# RP2350 register map
Vendor: Raspberry Pi; Series: RP; File version: 0.1
CPU: CM33 r1p0, little endian, MPU, FPU, DSP, VTOR, 4 interrupt priority bits, 52 interrupts, 8 SAU regions
Registers are 32-bit, read-write, reset 0x0 unless marked. A register's access mark holds for its fields unless they carry their own. Offsets are from the block's base; [hi:lo] are bit positions; {n}, {i} and the like mark numbered series; <NAME> marks a mode.

## DMA — DMA with separate read and write masters
Base 0x50000000
{0x0+0x40*i} CH{i}_READ_ADDR (i=0..15) — DMA Channel {i} Read Address pointer
  [31:0] CH{i}_READ_ADDR — This register updates automatically each time a read completes. The current value is the next address to be read by this channel.
{0x4+0x40*i} CH{i}_WRITE_ADDR (i=0..15) — DMA Channel {i} Write Address pointer
  [31:0] CH{i}_WRITE_ADDR — This register updates automatically each time a write completes. The current value is the next address to be written by this channel.
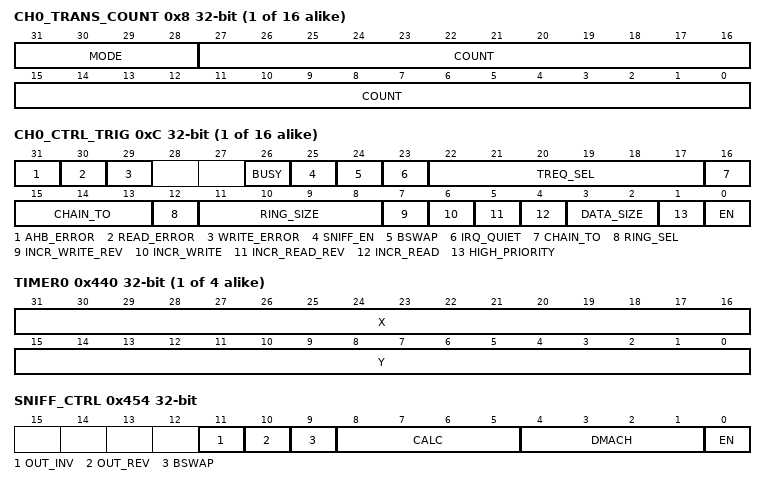
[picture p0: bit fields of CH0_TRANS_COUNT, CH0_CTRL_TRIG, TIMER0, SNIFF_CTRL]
{0x8+0x40*i} CH{i}_TRANS_COUNT (i=0..15) — DMA Channel {i} Transfer Count
  [31:28] MODE — When MODE is 0x0, the transfer count decrements with each transfer until 0, and then the channel triggers the next channel indicated by CTRL_CHAIN_TO. When MODE is 0x1, the transfer count decrements with each transfer until 0, and then the channel re-triggers itself, in addition to the trigger indicated by CTRL_CHAIN_TO. This is useful for e.g. an endless ring-buffer DMA with periodic interrupts. When MODE is 0xf, the transfer count does not decrement. The DMA channel performs an endless sequence of transfers, never triggering other channels or raising interrupts, until an ABORT is raised. All other values are reserved.
    0=NORMAL; 1=TRIGGER_SELF; 15=ENDLESS
  [27:0] COUNT — 28-bit transfer count (256 million transfers maximum). Program the number of bus transfers a channel will perform before halting. Note that, if transfers are larger than one byte in size, this is not equal to the number of bytes transferred (see CTRL_DATA_SIZE). When the channel is active, reading this register shows the number of transfers remaining, updating automatically each time a write transfer completes. Writing this register sets the RELOAD value for the transfer counter. Each time this channel is triggered, the RELOAD value is copied into the live transfer counter. The channel can be started multiple times, and will perform the same number of transfers each time, as programmed by most recent write. The RELOAD value can be observed at CHx_DBG_TCR. If TRANS_COUNT is used as a trigger, the written value is used immediately as the length of the new transfer sequence, as well as being written to RELOAD.
{0xC+0x40*i} CH{i}_CTRL_TRIG (i=0..15) — DMA Channel {i} Control and Status
  [31] AHB_ERROR ro — Logical OR of the READ_ERROR and WRITE_ERROR flags. The channel halts when it encounters any bus error, and always raises its channel IRQ flag.
  [30] READ_ERROR write-1-clears — If 1, the channel received a read bus error. Write one to clear. READ_ADDR shows the approximate address where the bus error was encountered (will not be earlier, or more than 3 transfers later)
  [29] WRITE_ERROR write-1-clears — If 1, the channel received a write bus error. Write one to clear. WRITE_ADDR shows the approximate address where the bus error was encountered (will not be earlier, or more than 5 transfers later)
  [26] BUSY ro — This flag goes high when the channel starts a new transfer sequence, and low when the last transfer of that sequence completes. Clearing EN while BUSY is high pauses the channel, and BUSY will stay high while paused. To terminate a sequence early (and clear the BUSY flag), see CHAN_ABORT.
  [25] SNIFF_EN — If 1, this channel's data transfers are visible to the sniff hardware, and each transfer will advance the state of the checksum. This only applies if the sniff hardware is enabled, and has this channel selected. This allows checksum to be enabled or disabled on a per-control- block basis.
  [24] BSWAP — Apply byte-swap transformation to DMA data. For byte data, this has no effect. For halfword data, the two bytes of each halfword are swapped. For word data, the four bytes of each word are swapped to reverse order.
  [23] IRQ_QUIET — In QUIET mode, the channel does not generate IRQs at the end of every transfer block. Instead, an IRQ is raised when NULL is written to a trigger register, indicating the end of a control block chain. This reduces the number of interrupts to be serviced by the CPU when transferring a DMA chain of many small control blocks.
  [22:17] TREQ_SEL — Select a Transfer Request signal. The channel uses the transfer request signal to pace its data transfer rate. Sources for TREQ signals are internal (TIMERS) or external (DREQ, a Data Request from the system). 0x0 to 0x3a -> select DREQ n as TREQ
    {v}=PIO0_TX{v} (Select PIO0's TX FIFO {v} as TREQ) (v=0..3); {v}=PIO0_RX{v-4} (Select PIO0's RX FIFO {v-4} as TREQ) (v=4..7); {v}=PIO1_TX{v-8} (Select PIO1's TX FIFO {v-8} as TREQ) (v=8..11); {v}=PIO1_RX{v-12} (Select PIO1's RX FIFO {v-12} as TREQ) (v=12..15); {v}=PIO2_TX{v-16} (Select PIO2's TX FIFO {v-16} as TREQ) (v=16..19); {v}=PIO2_RX{v-20} (Select PIO2's RX FIFO {v-20} as TREQ) (v=20..23); 24=SPI0_TX (Select SPI0's TX FIFO as TREQ); 25=SPI0_RX (Select SPI0's RX FIFO as TREQ); 26=SPI1_TX (Select SPI1's TX FIFO as TREQ); 27=SPI1_RX (Select SPI1's RX FIFO as TREQ); 28=UART0_TX (Select UART0's TX FIFO as TREQ); 29=UART0_RX (Select UART0's RX FIFO as TREQ); 30=UART1_TX (Select UART1's TX FIFO as TREQ); 31=UART1_RX (Select UART1's RX FIFO as TREQ); {v}=PWM_WRAP{v-32} (Select PWM Counter {v-32}'s Wrap Value as TREQ) (v=32..41); 42=PWM_WRAP10 (Select PWM Counter 0's Wrap Value as TREQ); 43=PWM_WRAP11 (Select PWM Counter 1's Wrap Value as TREQ); 44=I2C0_TX (Select I2C0's TX FIFO as TREQ); 45=I2C0_RX (Select I2C0's RX FIFO as TREQ); 46=I2C1_TX (Select I2C1's TX FIFO as TREQ); 47=I2C1_RX (Select I2C1's RX FIFO as TREQ); 48=ADC (Select the ADC as TREQ); 49=XIP_STREAM (Select the XIP Streaming FIFO as TREQ); 50=XIP_QMITX (Select XIP_QMITX as TREQ); 51=XIP_QMIRX (Select XIP_QMIRX as TREQ); 52=HSTX (Select HSTX as TREQ); 53=CORESIGHT (Select CORESIGHT as TREQ); 54=SHA256 (Select SHA256 as TREQ); 59=TIMER0 (Select Timer 0 as TREQ); 60=TIMER1 (Select Timer 1 as TREQ); 61=TIMER2 (Select Timer 2 as TREQ (Optional)); 62=TIMER3 (Select Timer 3 as TREQ (Optional)); 63=PERMANENT (Permanent request, for unpaced transfers.)
  [16:13] CHAIN_TO — When this channel completes, it will trigger the channel indicated by CHAIN_TO. Disable by setting CHAIN_TO = _(this channel)_. Note this field resets to 0, so channels 1 and above will chain to channel 0 by default. Set this field to avoid this behaviour.
  [12] RING_SEL — Select whether RING_SIZE applies to read or write addresses. If 0, read addresses are wrapped on a (1 << RING_SIZE) boundary. If 1, write addresses are wrapped.
  [11:8] RING_SIZE — Size of address wrap region. If 0, don't wrap. For values n > 0, only the lower n bits of the address will change. This wraps the address on a (1 << n) byte boundary, facilitating access to naturally-aligned ring buffers. Ring sizes between 2 and 32768 bytes are possible. This can apply to either read or write addresses, based on value of RING_SEL.
    0=RING_NONE
  [7] INCR_WRITE_REV — If 1, and INCR_WRITE is 1, the write address is decremented rather than incremented with each transfer. If 1, and INCR_WRITE is 0, this otherwise-unused combination causes the write address to be incremented by twice the transfer size, i.e. skipping over alternate addresses.
  [6] INCR_WRITE — If 1, the write address increments with each transfer. If 0, each write is directed to the same, initial address. Generally this should be disabled for memory-to-peripheral transfers.
  [5] INCR_READ_REV — If 1, and INCR_READ is 1, the read address is decremented rather than incremented with each transfer. If 1, and INCR_READ is 0, this otherwise-unused combination causes the read address to be incremented by twice the transfer size, i.e. skipping over alternate addresses.
  [4] INCR_READ — If 1, the read address increments with each transfer. If 0, each read is directed to the same, initial address. Generally this should be disabled for peripheral-to-memory transfers.
  [3:2] DATA_SIZE — Set the size of each bus transfer (byte/halfword/word). READ_ADDR and WRITE_ADDR advance by this amount (1/2/4 bytes) with each transfer.
    0=SIZE_BYTE; 1=SIZE_HALFWORD; 2=SIZE_WORD
  [1] HIGH_PRIORITY — HIGH_PRIORITY gives a channel preferential treatment in issue scheduling: in each scheduling round, all high priority channels are considered first, and then only a single low priority channel, before returning to the high priority channels. This only affects the order in which the DMA schedules channels. The DMA's bus priority is not changed. If the DMA is not saturated then a low priority channel will see no loss of throughput.
  [0] EN — DMA Channel Enable. When 1, the channel will respond to triggering events, which will cause it to become BUSY and start transferring data. When 0, the channel will ignore triggers, stop issuing transfers, and pause the current transfer sequence (i.e. BUSY will remain high if already high)
{0x10+0x40*i} CH{i}_AL1_CTRL reset not defined (i=0..15) — Alias for channel {i} CTRL register
  [31:0] CH{i}_AL1_CTRL — Pre-defined description
{0x14+0x40*i} CH{i}_AL1_READ_ADDR reset not defined (i=0..15) — Alias for channel {i} READ_ADDR register
  [31:0] CH{i}_AL1_READ_ADDR — Pre-defined description
{0x18+0x40*i} CH{i}_AL1_WRITE_ADDR reset not defined (i=0..15) — Alias for channel {i} WRITE_ADDR register
  [31:0] CH{i}_AL1_WRITE_ADDR — Pre-defined description
{0x1C+0x40*i} CH{i}_AL1_TRANS_COUNT_TRIG reset not defined (i=0..15) — Alias for channel {i} TRANS_COUNT register This is a trigger register (0xc). Writing a nonzero value will reload the channel counter and start the channel.
  [31:0] CH{i}_AL1_TRANS_COUNT_TRIG — Pre-defined description
{0x20+0x40*i} CH{i}_AL2_CTRL reset not defined (i=0..15) — Alias for channel {i} CTRL register
  [31:0] CH{i}_AL2_CTRL — Pre-defined description
{0x24+0x40*i} CH{i}_AL2_TRANS_COUNT reset not defined (i=0..15) — Alias for channel {i} TRANS_COUNT register
  [31:0] CH{i}_AL2_TRANS_COUNT — Pre-defined description
{0x28+0x40*i} CH{i}_AL2_READ_ADDR reset not defined (i=0..15) — Alias for channel {i} READ_ADDR register
  [31:0] CH{i}_AL2_READ_ADDR — Pre-defined description
{0x2C+0x40*i} CH{i}_AL2_WRITE_ADDR_TRIG reset not defined (i=0..15) — Alias for channel {i} WRITE_ADDR register This is a trigger register (0xc). Writing a nonzero value will reload the channel counter and start the channel.
  [31:0] CH{i}_AL2_WRITE_ADDR_TRIG — Pre-defined description
{0x30+0x40*i} CH{i}_AL3_CTRL reset not defined (i=0..15) — Alias for channel {i} CTRL register
  [31:0] CH{i}_AL3_CTRL — Pre-defined description
{0x34+0x40*i} CH{i}_AL3_WRITE_ADDR reset not defined (i=0..15) — Alias for channel {i} WRITE_ADDR register
  [31:0] CH{i}_AL3_WRITE_ADDR — Pre-defined description
{0x38+0x40*i} CH{i}_AL3_TRANS_COUNT reset not defined (i=0..15) — Alias for channel {i} TRANS_COUNT register
  [31:0] CH{i}_AL3_TRANS_COUNT — Pre-defined description
{0x3C+0x40*i} CH{i}_AL3_READ_ADDR_TRIG reset not defined (i=0..15) — Alias for channel {i} READ_ADDR register This is a trigger register (0xc). Writing a nonzero value will reload the channel counter and start the channel.
  [31:0] CH{i}_AL3_READ_ADDR_TRIG — Pre-defined description
0x400 INTR — Interrupt Status (raw)
  [15:0] INTR write-1-clears — Raw interrupt status for DMA Channels 0..15. Bit n corresponds to channel n. Ignores any masking or forcing. Channel interrupts can be cleared by writing a bit mask to INTR or INTS0/1/2/3. Channel interrupts can be routed to either of four system-level IRQs based on INTE0, INTE1, INTE2 and INTE3. The multiple system-level interrupts might be used to allow NVIC IRQ preemption for more time-critical channels, to spread IRQ load across different cores, or to target IRQs to different security domains. It is also valid to ignore the multiple IRQs, and just use INTE0/INTS0/IRQ 0. If this register is accessed at a security/privilege level less than that of a given channel (as defined by that channel's SECCFG_CHx register), then that channel's interrupt status will read as 0, ignore writes.
{0x404+0x10*i} INTE{i} (i=0..3) — Interrupt Enables for IRQ {i}
  [15:0] INTE{i} — Set bit n to pass interrupts from channel n to DMA IRQ {i}. Note this bit has no effect if the channel security/privilege level, defined by SECCFG_CHx, is greater than the IRQ security/privilege defined by SECCFG_IRQ{i}.
{0x408+0x10*i} INTF{i} (i=0..3) — Force Interrupts
  [15:0] INTF{i} — Write 1s to force the corresponding bits in INTS{i}. The interrupt remains asserted until INTF{i} is cleared.
{0x40C+0x10*i} INTS{i} (i=0..3) — Interrupt Status for IRQ {i}
  [15:0] INTS{i} write-1-clears — Indicates active channel interrupt requests which are currently causing IRQ {i} to be asserted. Channel interrupts can be cleared by writing a bit mask here. Channels with a security/privilege (SECCFG_CHx) greater SECCFG_IRQ{i}) read as 0 in this register, and ignore writes.
{0x400+0x10*i} INTR{i} (i=1..3) — Interrupt Status (raw)
  [15:0] INTR{i} write-1-clears — Raw interrupt status for DMA Channels 0..15. Bit n corresponds to channel n. Ignores any masking or forcing. Channel interrupts can be cleared by writing a bit mask to INTR or INTS0/1/2/3. Channel interrupts can be routed to either of four system-level IRQs based on INTE0, INTE1, INTE2 and INTE3. The multiple system-level interrupts might be used to allow NVIC IRQ preemption for more time-critical channels, to spread IRQ load across different cores, or to target IRQs to different security domains. It is also valid to ignore the multiple IRQs, and just use INTE0/INTS0/IRQ 0. If this register is accessed at a security/privilege level less than that of a given channel (as defined by that channel's SECCFG_CHx register), then that channel's interrupt status will read as 0, ignore writes.
{0x440+4i} TIMER{i} (i=0..3) — Pacing (X/Y) fractional timer The pacing timer produces TREQ assertions at a rate set by ((X/Y) * sys_clk). This equation is evaluated every sys_clk cycles and therefore can only generate TREQs at a rate of 1 per sys_clk (i.e. permanent TREQ) or less.
  [31:16] X — Pacing Timer Dividend. Specifies the X value for the (X/Y) fractional timer.
  [15:0] Y — Pacing Timer Divisor. Specifies the Y value for the (X/Y) fractional timer.
0x450 MULTI_CHAN_TRIGGER — Trigger one or more channels simultaneously
  [15:0] MULTI_CHAN_TRIGGER wo — Each bit in this register corresponds to a DMA channel. Writing a 1 to the relevant bit is the same as writing to that channel's trigger register; the channel will start if it is currently enabled and not already busy.
0x454 SNIFF_CTRL — Sniffer Control
  [11] OUT_INV — If set, the result appears inverted (bitwise complement) when read. This does not affect the way the checksum is calculated; the result is transformed on-the-fly between the result register and the bus.
  [10] OUT_REV — If set, the result appears bit-reversed when read. This does not affect the way the checksum is calculated; the result is transformed on-the-fly between the result register and the bus.
  [9] BSWAP — Locally perform a byte reverse on the sniffed data, before feeding into checksum. Note that the sniff hardware is downstream of the DMA channel byteswap performed in the read master: if channel CTRL_BSWAP and SNIFF_CTRL_BSWAP are both enabled, their effects cancel from the sniffer's point of view.
  [8:5] CALC — Pre-defined description
    0=CRC32 (Calculate a CRC-32 (IEEE802.3 polynomial)); 1=CRC32R (Calculate a CRC-32 (IEEE802.3 polynomial) with bit reversed data); 2=CRC16 (Calculate a CRC-16-CCITT); 3=CRC16R (Calculate a CRC-16-CCITT with bit reversed data); 14=EVEN (XOR reduction over all data. == 1 if the total 1 population count is odd.); 15=SUM (Calculate a simple 32-bit checksum (addition with a 32 bit accumulator))
  [4:1] DMACH — DMA channel for Sniffer to observe
  [0] EN — Enable sniffer
0x458 SNIFF_DATA — Data accumulator for sniff hardware
  [31:0] SNIFF_DATA — Write an initial seed value here before starting a DMA transfer on the channel indicated by SNIFF_CTRL_DMACH. The hardware will update this register each time it observes a read from the indicated channel. Once the channel completes, the final result can be read from this register.
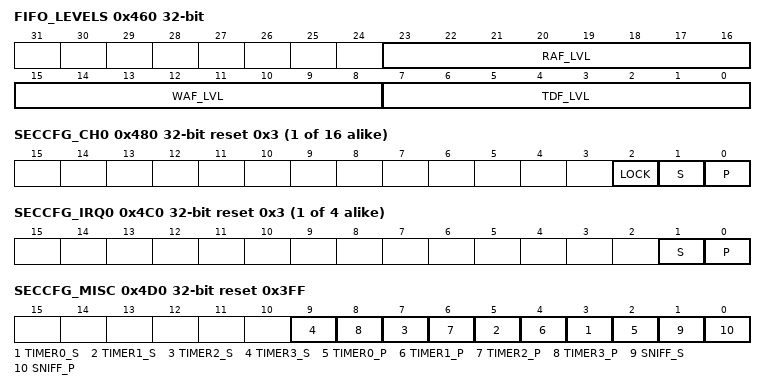
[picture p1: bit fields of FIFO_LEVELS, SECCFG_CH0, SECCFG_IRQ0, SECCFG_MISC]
0x460 FIFO_LEVELS — Debug RAF, WAF, TDF levels
  [23:16] RAF_LVL ro — Current Read-Address-FIFO fill level
  [15:8] WAF_LVL ro — Current Write-Address-FIFO fill level
  [7:0] TDF_LVL ro — Current Transfer-Data-FIFO fill level
0x464 CHAN_ABORT — Abort an in-progress transfer sequence on one or more channels
  [15:0] CHAN_ABORT wo — Each bit corresponds to a channel. Writing a 1 aborts whatever transfer sequence is in progress on that channel. The bit will remain high until any in-flight transfers have been flushed through the address and data FIFOs. After writing, this register must be polled until it returns all-zero. Until this point, it is unsafe to restart the channel.
0x468 N_CHANNELS reset not defined — The number of channels this DMA instance is equipped with. This DMA supports up to 16 hardware channels, but can be configured with as few as one, to minimise silicon area.
  [4:0] N_CHANNELS ro — Pre-defined description
{0x480+4i} SECCFG_CH{i} reset 0x3 (i=0..15) — Security configuration for channel {i}. Control whether this channel performs Secure/Non-secure and Privileged/Unprivileged bus accesses. If this channel generates bus accesses of some security level, an access of at least that level (in the order S+P > S+U > NS+P > NS+U) is required to program, trigger, abort, check the status of, interrupt on or acknowledge the interrupt of this channel. This register automatically locks down (becomes read-only) once software starts to configure the channel. This register is world-readable, but is writable only from a Secure, Privileged context.
  [2] LOCK — LOCK is 0 at reset, and is set to 1 automatically upon a successful write to this channel's control registers. That is, a write to CTRL, READ_ADDR, WRITE_ADDR, TRANS_COUNT and their aliases. Once its LOCK bit is set, this register becomes read-only. A failed write, for example due to the write's privilege being lower than that specified in the channel's SECCFG register, will not set the LOCK bit.
  [1] S — Secure channel. If 1, this channel performs Secure bus accesses. If 0, it performs Non-secure bus accesses. If 1, this channel is controllable only from a Secure context.
  [0] P — Privileged channel. If 1, this channel performs Privileged bus accesses. If 0, it performs Unprivileged bus accesses. If 1, this channel is controllable only from a Privileged context of the same Secure/Non-secure level, or any context of a higher Secure/Non-secure level.
{0x4C0+4i} SECCFG_IRQ{i} reset 0x3 (i=0..3) — Security configuration for IRQ {i}. Control whether the IRQ permits configuration by Non-secure/Unprivileged contexts, and whether it can observe Secure/Privileged channel interrupt flags.
  [1] S — Secure IRQ. If 1, this IRQ's control registers can only be accessed from a Secure context. If 0, this IRQ's control registers can be accessed from a Non-secure context, but Secure channels (as per SECCFG_CHx) are masked from the IRQ status, and this IRQ's registers can not be used to acknowledge the channel interrupts of Secure channels.
  [0] P — Privileged IRQ. If 1, this IRQ's control registers can only be accessed from a Privileged context. If 0, this IRQ's control registers can be accessed from an Unprivileged context, but Privileged channels (as per SECCFG_CHx) are masked from the IRQ status, and this IRQ's registers can not be used to acknowledge the channel interrupts of Privileged channels.
0x4D0 SECCFG_MISC reset 0x3FF — Miscellaneous security configuration
  [2n+3] TIMER{n}_S (n=0..3) — If 1, the TIMER{n} register is only accessible from a Secure context, and timer DREQ {n} is only visible to Secure channels.
  [2n+2] TIMER{n}_P (n=0..3) — If 1, the TIMER{n} register is only accessible from a Privileged (or more Secure) context, and timer DREQ {n} is only visible to Privileged (or more Secure) channels.
  [1] SNIFF_S — If 1, the sniffer can see data transfers from Secure channels, and can itself only be accessed from a Secure context. If 0, the sniffer can be accessed from either a Secure or Non-secure context, but can not see data transfers of Secure channels.
  [0] SNIFF_P — If 1, the sniffer can see data transfers from Privileged channels, and can itself only be accessed from a privileged context, or from a Secure context when SNIFF_S is 0. If 0, the sniffer can be accessed from either a Privileged or Unprivileged context (with sufficient security level) but can not see transfers from Privileged channels.
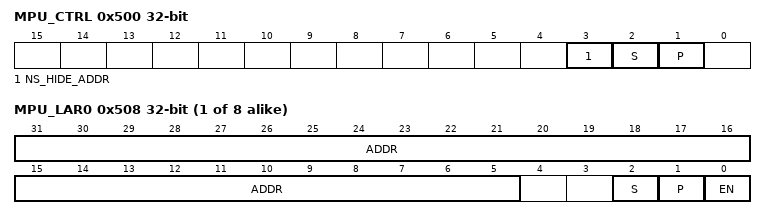
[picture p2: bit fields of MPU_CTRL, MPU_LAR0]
0x500 MPU_CTRL — Control register for DMA MPU. Accessible only from a Privileged context.
  [3] NS_HIDE_ADDR — By default, when a region's S bit is clear, Non-secure-Privileged reads can see the region's base address and limit address. Set this bit to make the addresses appear as 0 to Non-secure reads, even when the region is Non-secure, to avoid leaking information about the processor SAU map.
  [2] S — Determine whether an address not covered by an active MPU region is Secure (1) or Non-secure (0)
  [1] P — Determine whether an address not covered by an active MPU region is Privileged (1) or Unprivileged (0)
{0x504+8i} MPU_BAR{i} (i=0..7) — Base address register for MPU region {i}. Writable only from a Secure, Privileged context.
  [31:5] ADDR — This MPU region matches addresses where addr[31:5] (the 27 most significant bits) are greater than or equal to BAR_ADDR, and less than or equal to LAR_ADDR. Readable from any Privileged context, if and only if this region's S bit is clear, and MPU_CTRL_NS_HIDE_ADDR is clear. Otherwise readable only from a Secure, Privileged context.
{0x508+8i} MPU_LAR{i} (i=0..7) — Limit address register for MPU region {i}. Writable only from a Secure, Privileged context, with the exception of the P bit.
  [31:5] ADDR — Limit address bits 31:5. Readable from any Privileged context, if and only if this region's S bit is clear, and MPU_CTRL_NS_HIDE_ADDR is clear. Otherwise readable only from a Secure, Privileged context.
  [2] S — Determines the Secure/Non-secure (=1/0) status of addresses matching this region, if this region is enabled.
  [1] P — Determines the Privileged/Unprivileged (=1/0) status of addresses matching this region, if this region is enabled. Writable from any Privileged context, if and only if the S bit is clear. Otherwise, writable only from a Secure, Privileged context.
  [0] EN — Region enable. If 1, any address within range specified by the base address (BAR_ADDR) and limit address (LAR_ADDR) has the attributes specified by S and P.
{0x800+0x40*i} CH{i}_DBG_CTDREQ (i=0..15) — Read: get channel DREQ counter (i.e. how many accesses the DMA expects it can perform on the peripheral without overflow/underflow. Write any value: clears the counter, and cause channel to re-initiate DREQ handshake.
  [5:0] CH{i}_DBG_CTDREQ write-1-clears — Pre-defined description
{0x804+0x40*i} CH{i}_DBG_TCR (i=0..15) — Read to get channel TRANS_COUNT reload value, i.e. the length of the next transfer
  [31:0] CH{i}_DBG_TCR ro — Pre-defined description
